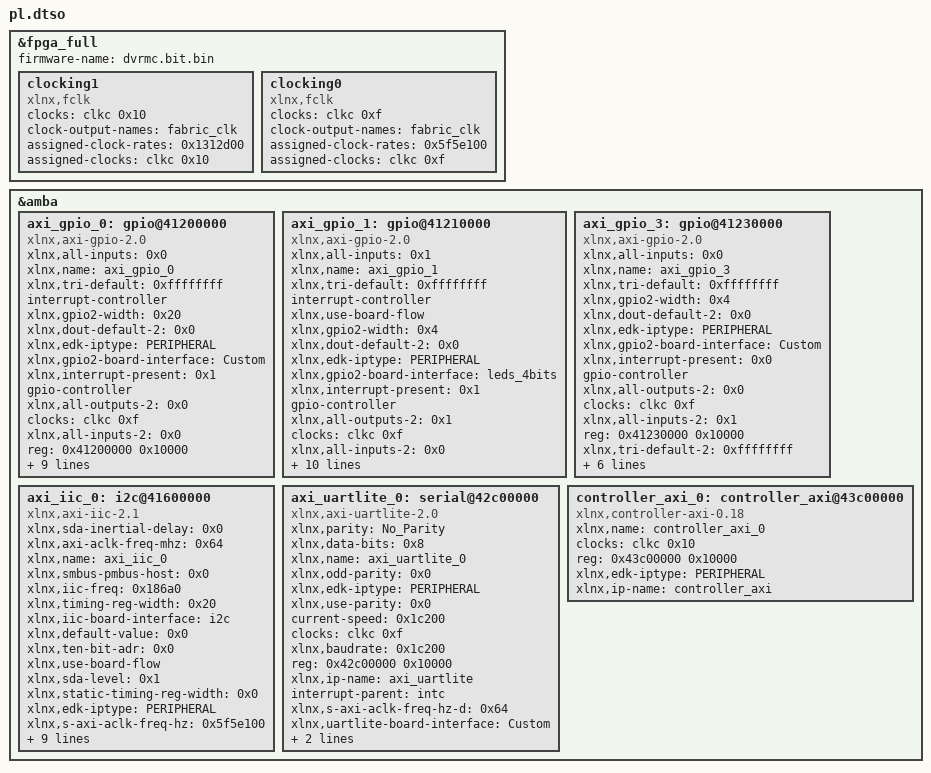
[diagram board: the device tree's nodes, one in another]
/dts-v1/;
/plugin/;

&fpga_full {
        firmware-name = "dvrmc.bit.bin";

        clocking1: clocking1 {
                clocks = <&clkc 0x10>;
                clock-output-names = "fabric_clk";
                #clock-cells = <0x0>;
                assigned-clock-rates = <0x1312d00>;
                assigned-clocks = <&clkc 0x10>;
                compatible = "xlnx,fclk";
        };

        clocking0: clocking0 {
                clocks = <&clkc 0xf>;
                clock-output-names = "fabric_clk";
                #clock-cells = <0x0>;
                assigned-clock-rates = <0x5f5e100>;
                assigned-clocks = <&clkc 0xf>;
                compatible = "xlnx,fclk";
        };
};

&amba {
        #address-cells = <1>;
        #size-cells = <1>;

        axi_gpio_0: gpio@41200000 {
                xlnx,all-inputs = <0x0>;
                xlnx,name = "axi_gpio_0";
                xlnx,tri-default = <0xffffffff>;
                interrupt-names = "ip2intc_irpt";
                interrupt-controller;
                clock-names = "s_axi_aclk";
                xlnx,gpio2-width = <0x20>;
                xlnx,dout-default-2 = <0x0>;
                xlnx,edk-iptype = "PERIPHERAL";
                xlnx,gpio2-board-interface = "Custom";
                xlnx,interrupt-present = <0x1>;
                device_type = "gpio";
                gpio-controller;
                xlnx,all-outputs-2 = <0x0>;
                clocks = <&clkc 0xf>;
                xlnx,all-inputs-2 = <0x0>;
                reg = <0x41200000 0x10000>;
                xlnx,tri-default-2 = <0xffffffff>;
                xlnx,ip-name = "axi_gpio";
                xlnx,is-dual = <0x0>;
                xlnx,dout-default = <0x0>;
                interrupt-parent = <&intc>;
                xlnx,gpio-width = <0x6>;
                #gpio-cells = <0x2>;
                xlnx,all-outputs = <0x1>;
                compatible = "xlnx,axi-gpio-2.0", "xlnx,xps-gpio-1.00.a";
                xlnx,gpio-board-interface = "Custom";
                interrupts = <0x0 0x1f 0x4>;
                #interrupt-cells = <0x2>;
        };

        axi_gpio_1: gpio@41210000 {
                xlnx,all-inputs = <0x1>;
                xlnx,name = "axi_gpio_1";
                xlnx,tri-default = <0xffffffff>;
                interrupt-names = "ip2intc_irpt";
                interrupt-controller;
                xlnx,use-board-flow;
                clock-names = "s_axi_aclk";
                xlnx,gpio2-width = <0x4>;
                xlnx,dout-default-2 = <0x0>;
                xlnx,edk-iptype = "PERIPHERAL";
                xlnx,gpio2-board-interface = "leds_4bits";
                xlnx,interrupt-present = <0x1>;
                device_type = "gpio";
                gpio-controller;
                xlnx,all-outputs-2 = <0x1>;
                clocks = <&clkc 0xf>;
                xlnx,all-inputs-2 = <0x0>;
                reg = <0x41210000 0x10000>;
                xlnx,tri-default-2 = <0xffffffff>;
                xlnx,ip-name = "axi_gpio";
                xlnx,is-dual = <0x1>;
                xlnx,dout-default = <0x0>;
                interrupt-parent = <&intc>;
                xlnx,gpio-width = <0x4>;
                #gpio-cells = <0x2>;
                xlnx,all-outputs = <0x0>;
                compatible = "xlnx,axi-gpio-2.0", "xlnx,xps-gpio-1.00.a";
                xlnx,gpio-board-interface = "btns_4bits";
                interrupts = <0x0 0x20 0x4>;
                #interrupt-cells = <0x2>;
        };

        axi_gpio_3: gpio@41230000 {
                xlnx,all-inputs = <0x0>;
                xlnx,name = "axi_gpio_3";
                xlnx,tri-default = <0xffffffff>;
                clock-names = "s_axi_aclk";
                xlnx,gpio2-width = <0x4>;
                xlnx,dout-default-2 = <0x0>;
                xlnx,edk-iptype = "PERIPHERAL";
                xlnx,gpio2-board-interface = "Custom";
                xlnx,interrupt-present = <0x0>;
                device_type = "gpio";
                gpio-controller;
                xlnx,all-outputs-2 = <0x0>;
                clocks = <&clkc 0xf>;
                xlnx,all-inputs-2 = <0x1>;
                reg = <0x41230000 0x10000>;
                xlnx,tri-default-2 = <0xffffffff>;
                xlnx,ip-name = "axi_gpio";
                xlnx,is-dual = <0x1>;
                xlnx,dout-default = <0x0>;
                xlnx,gpio-width = <0x1>;
                #gpio-cells = <0x2>;
                xlnx,all-outputs = <0x1>;
                compatible = "xlnx,axi-gpio-2.0", "xlnx,xps-gpio-1.00.a";
                xlnx,gpio-board-interface = "Custom";
        };

        axi_iic_0: i2c@41600000 {
                xlnx,sda-inertial-delay = <0x0>;
                xlnx,axi-aclk-freq-mhz = <0x64>;
                xlnx,name = "axi_iic_0";
                xlnx,smbus-pmbus-host = <0x0>;
                xlnx,iic-freq = <0x186a0>;
                xlnx,timing-reg-width = <0x20>;
                xlnx,iic-board-interface = "i2c";
                interrupt-names = "iic2intc_irpt";
                xlnx,default-value = <0x0>;
                xlnx,ten-bit-adr = <0x0>;
                xlnx,use-board-flow;
                clock-names = "s_axi_aclk";
                xlnx,sda-level = <0x1>;
                xlnx,static-timing-reg-width = <0x0>;
                xlnx,edk-iptype = "PERIPHERAL";
                xlnx,s-axi-aclk-freq-hz = <0x5f5e100>;
                xlnx,gpo-width = <0x1>;
                clocks = <&clkc 0xf>;
                reg = <0x41600000 0x10000>;
                xlnx,disable-setup-violation-check = <0x0>;
                xlnx,ip-name = "axi_iic";
                interrupt-parent = <&intc>;
                xlnx,scl-inertial-delay = <0x0>;
                compatible = "xlnx,axi-iic-2.1", "xlnx,xps-iic-2.00.a";
                xlnx,iic-freq-khz = <0x64>;
                interrupts = <0x0 0x1e 0x4>;
        };

        axi_uartlite_0: serial@42c00000 {
                xlnx,parity = "No_Parity";
                xlnx,data-bits = <0x8>;
                xlnx,name = "axi_uartlite_0";
                interrupt-names = "interrupt";
                clock-names = "s_axi_aclk";
                xlnx,odd-parity = <0x0>;
                xlnx,edk-iptype = "PERIPHERAL";
                xlnx,use-parity = <0x0>;
                device_type = "serial";
                current-speed = <0x1c200>;
                clocks = <&clkc 0xf>;
                xlnx,baudrate = <0x1c200>;
                reg = <0x42c00000 0x10000>;
                xlnx,ip-name = "axi_uartlite";
                interrupt-parent = <&intc>;
                xlnx,s-axi-aclk-freq-hz-d = <0x64>;
                xlnx,uartlite-board-interface = "Custom";
                port-number = <0x0>;
                compatible = "xlnx,axi-uartlite-2.0", "xlnx,xps-uartlite-1.00.a";
                interrupts = <0x0 0x1d 0x1>;
        };

        controller_axi_0: controller_axi@43c00000 {
                xlnx,name = "controller_axi_0";
                clocks = <&clkc 0x10>;
                reg = <0x43c00000 0x10000>;
                xlnx,edk-iptype = "PERIPHERAL";
                xlnx,ip-name = "controller_axi";
                clock-names = "clk";
                compatible = "xlnx,controller-axi-0.18";
        };
};

